# CEC1712H_N2_SX register map
Vendor: Microchip Technology; Series: CEC1712H_N2_SX; File version: 0
CPU: CM4 r1p0, little endian, no MPU, 3 interrupt priority bits, 172 interrupts
Registers are 32-bit, read-write, reset 0x0 unless marked. A register's access mark holds for its fields unless they carry their own. Offsets are from the block's base; [hi:lo] are bit positions; {n}, {i} and the like mark numbered series; 'fields as' and 'values as' point back to an identical list.

## HTM0 — The Hibernation Timer can generate a wake event to the Embedded Controller (EC) when it is in a hibernation mode
Base 0x40009800; register names take the prefix HTM_
Same registers: HTM1 0x40009820
0x00 PRLD 16-bit — [15:0] This register is used to set the Hibernation Timer Preload value.
0x04 CTRL 16-bit — HTimer Control Register
  [0] CTRL — 1= The Hibernation Timer has a resolution of 0.125s per LSB, which yields a maximum time in excess of 2 hours. 0= The Hibernation Timer has a resolution of 30.5us per LSB, which yields a maximum time of ~2seconds.
0x08 CNT 16-bit ro — The current state of the Hibernation Timer.

## RTOS — RTOS is a 32-bit timer designed to operate on the 32kHz oscillator which is available during all chip sleep states.
Base 0x40007400; register names take the prefix RTOS_
0x00 CNT — RTOS Timer Count Register.
  [31:0] CNTR — This register contains the current value of the RTOS Timer counter. This register should be read as a DWORD. There is no latching mechanism of the upper bytes implemented if the register is accessed as a byte or word. Reading the register with byte or word operations may give incorrect results.
0x04 PRLD — RTOS Timer Preload Register
  [31:0] PRELOAD — The this register is loaded into the RTOS Timer counter either when the TIMER_START bit is written with a 1, or when the timer counter counts down to 0 and the AUTO_RELOAD bit is 1. This register must be programmed with a new count value before the TIMER_START bit is set to 1. If this register is updated while the counter is operating, the new count value will only take effect if the counter transitions form 1 to 0 while the AUTO_RELOAD bit is set.
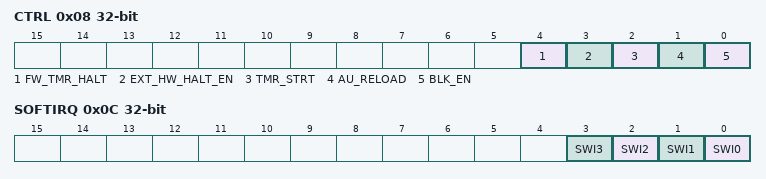
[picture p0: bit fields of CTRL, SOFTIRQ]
0x08 CTRL — RTOS Timer Control Register
  [4] FW_TMR_HALT — 1=The timer counter is halted. If the counter was running, clearing this bit will restart the counter from the value at which it halted. 0=The timer counter, if enabled, will continue to run
  [3] EXT_HW_HALT_EN — 1=The timer counter is halted when the external HALT signal is asserted. Counting is always enabled if HALT is de-asserted. 0=The HALT signal does not affect the RTOS Timer
  [2] TMR_STRT — Writing a 1 to this bit will load the timer counter with the RTOS Timer Preload Register and start counting. If the Preload Register is 0, counting will not start and this bit will be cleared to 0. Writing a 0 to this bit will halt the counter and clear its contents to 0. The RTOS timer interrupt will not be generated. This bit is automatically cleared if the AUTO_RELOAD bit is 0 and the timer counter transitions from 1 to 0.
  [1] AU_RELOAD — 1=The the RTOS Timer Preload Register is loaded into the timer counter and the counter is restarted when the counter transitions from 1 to 0. 0=The timer counter halts when it transitions from 1 to 0 and will not restart.
  [0] BLK_EN — 1=RTOS timer counter is enabled. 0=RTOS timer disabled. All register bits are reset to their default state
0x0C SOFTIRQ wo — Soft Interrupt Register
  [n] SWI{n} (n=0..3) — Software Interrupt. A write of a '1' to this bit will generate an SWI interrupt to the EC. Writes of a '0' have no effect. Reads return '0'.

## RTC — This is the set of registers that are automatically counted by hardware every 1 second while the block is enabled
Base 0x400F5000; register names take the prefix RTC_
0x00 SEC 8-bit — Seconds Register
0x01 SEC_ALARM 8-bit — Seconds Alarm Register
0x02 MIN 8-bit — Minutes Register
0x03 MIN_ALARM 8-bit — Minutes Alarm Register
0x04 HR 8-bit — Hours Register
0x05 HR_ALARM 8-bit — Hours Alarm Register
0x06 DAY_OF_WK 8-bit — Day of Week Register
0x07 DAY_OF_MON 8-bit — Day of Month Register
0x08 MONTH 8-bit
0x09 YEAR 8-bit
0x0A REGA 8-bit — Register A
0x0B REGB 8-bit — Register B
0x0C REGC 8-bit — Register C
0x0D REGD 8-bit — Register D
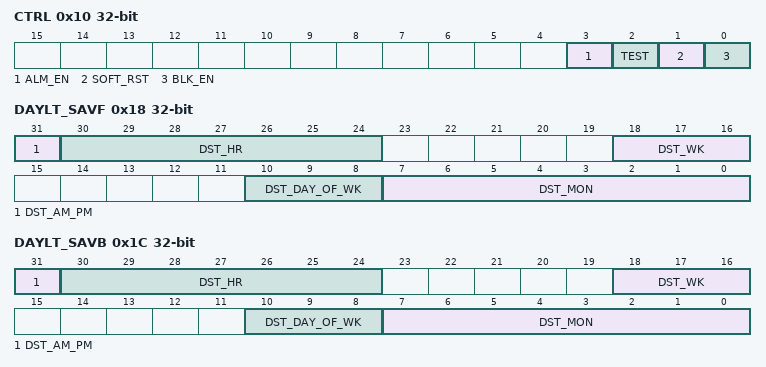
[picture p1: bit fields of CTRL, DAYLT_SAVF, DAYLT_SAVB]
0x10 CTRL — RTC Control Register
  [3] ALM_EN — ALARM_ENABLE 1=Enables the Alarm features, 0=Disables the Alarm features
  [2] TEST
  [1] SOFT_RST — SOFT_RESET A '1' written to this bit position will trigger the RTC_RST reset, resetting the block and all registers except this one and the Test Register. This bit is self-clearing at the end of the reset, one cycle of Host Bus Clock later, and so requires no waiting.
  [0] BLK_EN — BLOCK_ENABLE This bit must be '1' in order for the block to function internally. Registers may be initialized first, before setting this bit to '1' to start operation.
0x14 WK_ALARM reset 0xFF — Week Alarm Register[7:0] - ALARM_DAY_OF_WEEK This register, if written to a value in the range 1- -7, will inhibit the Alarm interrupt unless this field matches the contents of the Day of Week Register also.
0x18 DAYLT_SAVF — Daylight Savings Forward Register
  [31] DST_AM_PM — This bit selects AM vs. PM, to match bit[7] of the Hours Register if 12-Hour mode is selected in Register B at the time of writing.
  [30:24] DST_HR — This field holds the matching value for bits[6:0] of the Hours register. The written value will be interpreted according to the 24/12 Hour mode and DM mode settings at the time of writing.
  [18:16] DST_WK — 5=Last week of month, 4 =Fourth week of month, 3=Third week of month, 2=Second week of month, 1=First week of month
  [10:8] DST_DAY_OF_WK — This field matches the Day of Week Register bits[2:0].
  [7:0] DST_MON — This field matches the Month Register.
0x1C DAYLT_SAVB — Daylight Savings Backward Register
  fields as DAYLT_SAVF
